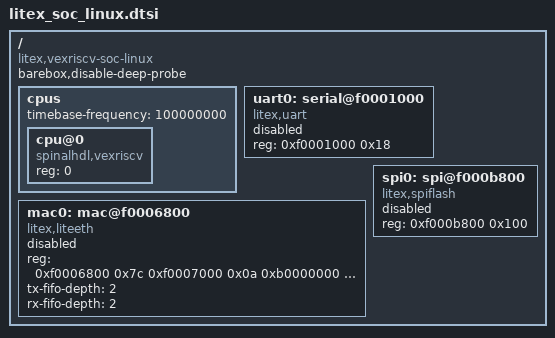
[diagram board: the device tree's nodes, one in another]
// SPDX-License-Identifier: GPL-2.0-only

/dts-v1/;

/ {
	compatible = "litex,vexriscv-soc-linux";
	barebox,disable-deep-probe;

	#address-cells = <1>;
	#size-cells = <1>;

	cpus {
		#address-cells = <1>;
		#size-cells = <0>;

		timebase-frequency = <100000000>; // 100 MHz

		cpu@0 {
			device_type = "cpu";
			compatible = "spinalhdl,vexriscv", "riscv";
			reg = <0>;
		};
	};

	uart0: serial@f0001000 {
		compatible = "litex,uart";
		reg = <0xf0001000 0x18>;
		status = "disabled";
	};

	mac0: mac@f0006800 {
		compatible = "litex,liteeth";
		reg = <0xf0006800 0x7c /* base */
			0xf0007000 0x0a /* mdio_base */
			0xb0000000 0x2000>; /* buf_base */
		tx-fifo-depth = <2>;
		rx-fifo-depth = <2>;
		status = "disabled";
	};

	spi0: spi@f000b800 {
		compatible = "litex,spiflash";

		#address-cells = <1>;
		#size-cells = <0>;

		reg = <0xf000b800 0x100>;
		status = "disabled";
	};
};
